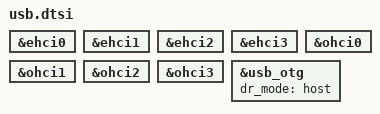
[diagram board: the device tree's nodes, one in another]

&ehci0 {
	status = "okay";
};

&ehci1 {
	status = "okay";
};

&ehci2 {
	status = "okay";
};

&ehci3 {
	status = "okay";
};

&ohci0 {
	status = "okay";
};

&ohci1 {
	status = "okay";
};

&ohci2 {
	status = "okay";
};

&ohci3 {
	status = "okay";
};

&usb_otg {
	dr_mode = "host";
	status = "okay";
};

